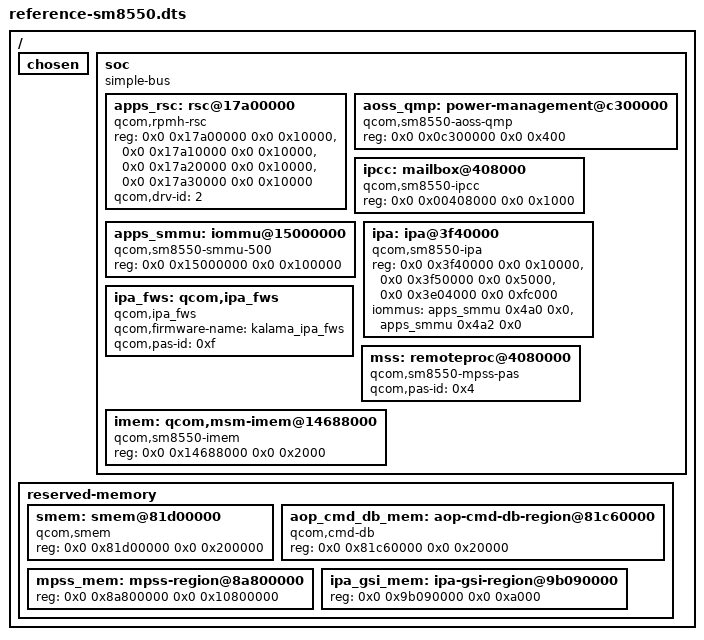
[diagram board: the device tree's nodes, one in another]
/dts-v1/;

/* A stand-in for the Xiaomi 13 Ultra's (ishtar, SM8550) device tree, reduced to the nodes */
/* tools/soc-args.py reads. The addresses are the ones upstream Linux's sm8550.dtsi gives. */
/* This exists to test the generator on the newer tree's shape: the SoC's name in the */
/* compatibles, the IPA's three named regions, two address cells under reserved-memory, and */
/* the iommus on the IPA's own node. */

/ {
	#address-cells = <2>;
	#size-cells = <2>;

	chosen { };

	soc {
		compatible = "simple-bus";
		#address-cells = <2>;
		#size-cells = <2>;
		ranges;

		apps_rsc: rsc@17a00000 {
			compatible = "qcom,rpmh-rsc";
			reg = <0x0 0x17a00000 0x0 0x10000>,
			      <0x0 0x17a10000 0x0 0x10000>,
			      <0x0 0x17a20000 0x0 0x10000>,
			      <0x0 0x17a30000 0x0 0x10000>;
			reg-names = "drv-0", "drv-1", "drv-2", "drv-3";
			qcom,drv-id = <2>;
		};

		aoss_qmp: power-management@c300000 {
			compatible = "qcom,sm8550-aoss-qmp", "qcom,aoss-qmp";
			reg = <0x0 0x0c300000 0x0 0x400>;
		};

		ipcc: mailbox@408000 {
			compatible = "qcom,sm8550-ipcc", "qcom,ipcc";
			reg = <0x0 0x00408000 0x0 0x1000>;
		};

		apps_smmu: iommu@15000000 {
			compatible = "qcom,sm8550-smmu-500", "qcom,smmu-500", "arm,mmu-500";
			reg = <0x0 0x15000000 0x0 0x100000>;
			#iommu-cells = <2>;
		};

		ipa: ipa@3f40000 {
			compatible = "qcom,sm8550-ipa";
			reg = <0x0 0x3f40000 0x0 0x10000>,
			      <0x0 0x3f50000 0x0 0x5000>,
			      <0x0 0x3e04000 0x0 0xfc000>;
			reg-names = "ipa-reg", "ipa-shared", "gsi";
			iommus = <&apps_smmu 0x4a0 0x0>,
				 <&apps_smmu 0x4a2 0x0>;
		};

		ipa_fws: qcom,ipa_fws {
			compatible = "qcom,ipa_fws";
			qcom,firmware-name = "kalama_ipa_fws";
			qcom,pas-id = <0xf>;
		};

		mss: remoteproc@4080000 {
			compatible = "qcom,sm8550-mpss-pas";
			qcom,pas-id = <0x4>;
		};

		imem: qcom,msm-imem@14688000 {
			compatible = "qcom,sm8550-imem", "qcom,msm-imem";
			reg = <0x0 0x14688000 0x0 0x2000>;
		};
	};

	reserved-memory {
		#address-cells = <2>;
		#size-cells = <2>;
		ranges;

		smem: smem@81d00000 {
			compatible = "qcom,smem";
			reg = <0x0 0x81d00000 0x0 0x200000>;
		};

		aop_cmd_db_mem: aop-cmd-db-region@81c60000 {
			compatible = "qcom,cmd-db";
			reg = <0x0 0x81c60000 0x0 0x20000>;
		};

		mpss_mem: mpss-region@8a800000 {
			reg = <0x0 0x8a800000 0x0 0x10800000>;
		};

		ipa_gsi_mem: ipa-gsi-region@9b090000 {
			reg = <0x0 0x9b090000 0x0 0xa000>;
		};
	};
};
